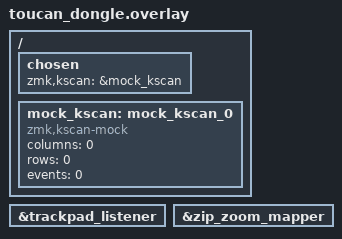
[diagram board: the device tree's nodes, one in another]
#include "toucan.dtsi"

// The dongle has no switch matrix of its own
/delete-node/ &kscan0;

/ {
    chosen {
        zmk,kscan = &mock_kscan;
    };

    mock_kscan: mock_kscan_0 {
        compatible = "zmk,kscan-mock";
        columns = <0>;
        rows = <0>;
        events = <0>;
    };
};

&trackpad_listener {
    status = "okay";
};

&zip_zoom_mapper {
    status = "okay";
};
